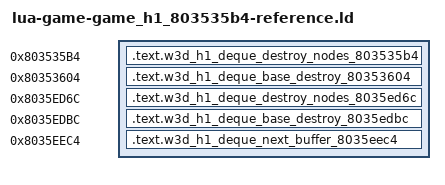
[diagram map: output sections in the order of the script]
/* Generated reference-only placements. All bodies are source-built. */
OUTPUT_FORMAT("elf32-powerpc")
OUTPUT_ARCH(powerpc)
ENTRY(w3d_h1_deque_destroy_nodes_803535b4)
_SDA_BASE_ = 0x804b2540;
_SDA2_BASE_ = 0x804c2540;
w3d_actor_member_delete_backend = 0x801fe1f8;
w3d_handle_storage_release = 0x802134fc;
SECTIONS {
  .text.w3d_h1_deque_destroy_nodes_803535b4 0x803535b4 : { *(.text.w3d_h1_deque_destroy_nodes_803535b4) }
  .text.w3d_h1_deque_base_destroy_80353604 0x80353604 : { *(.text.w3d_h1_deque_base_destroy_80353604) }
  .text.w3d_h1_deque_destroy_nodes_8035ed6c 0x8035ed6c : { *(.text.w3d_h1_deque_destroy_nodes_8035ed6c) }
  .text.w3d_h1_deque_base_destroy_8035edbc 0x8035edbc : { *(.text.w3d_h1_deque_base_destroy_8035edbc) }
  .text.w3d_h1_deque_next_buffer_8035eec4 0x8035eec4 : { *(.text.w3d_h1_deque_next_buffer_8035eec4) }
  /DISCARD/ : { *(.text*) *(.rodata*) *(.data*) *(.bss*) *(.sdata*) *(.sbss*) *(.comment) }
}
